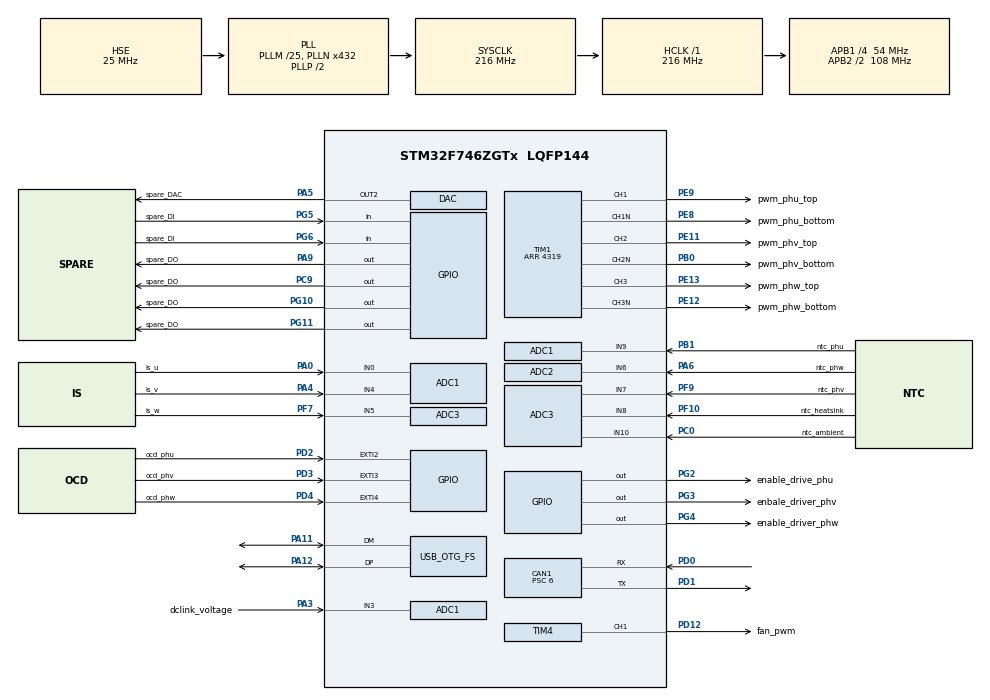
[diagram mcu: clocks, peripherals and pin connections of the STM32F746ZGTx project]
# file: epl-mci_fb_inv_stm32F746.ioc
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ADC1.Channel-0\#ChannelRegularConversion=ADC_CHANNEL_0
ADC1.Channel-1\#ChannelRegularConversion=ADC_CHANNEL_3
ADC1.Channel-2\#ChannelRegularConversion=ADC_CHANNEL_4
ADC1.Channel-3\#ChannelRegularConversion=ADC_CHANNEL_9
ADC1.ClockPrescaler=ADC_CLOCK_SYNC_PCLK_DIV4
ADC1.ContinuousConvMode=DISABLE
ADC1.DMAContinuousRequests=ENABLE
ADC1.EOCSelection=ADC_EOC_SEQ_CONV
ADC1.ExternalTrigConv=ADC_EXTERNALTRIGCONV_T1_TRGO2
ADC1.ExternalTrigConvEdge=ADC_EXTERNALTRIGCONVEDGE_RISING
ADC1.NbrOfConversion=4
ADC1.NbrOfConversionFlag=1
ADC1.Rank-0\#ChannelRegularConversion=1
ADC1.Rank-1\#ChannelRegularConversion=2
ADC1.Rank-2\#ChannelRegularConversion=3
ADC1.Rank-3\#ChannelRegularConversion=4
ADC1.SamplingTime-0\#ChannelRegularConversion=ADC_SAMPLETIME_3CYCLES
ADC1.SamplingTime-1\#ChannelRegularConversion=ADC_SAMPLETIME_3CYCLES
ADC1.SamplingTime-2\#ChannelRegularConversion=ADC_SAMPLETIME_3CYCLES
ADC1.SamplingTime-3\#ChannelRegularConversion=ADC_SAMPLETIME_3CYCLES
ADC1.master=1
ADC2.Channel-0\#ChannelRegularConversion=ADC_CHANNEL_0
ADC2.Channel-1\#ChannelRegularConversion=ADC_CHANNEL_3
ADC2.Channel-2\#ChannelRegularConversion=ADC_CHANNEL_4
ADC2.Channel-3\#ChannelRegularConversion=ADC_CHANNEL_6
ADC2.ClockPrescaler=ADC_CLOCK_SYNC_PCLK_DIV4
ADC2.ContinuousConvMode=DISABLE
ADC2.DMAContinuousRequests=ENABLE
ADC2.EOCSelection=ADC_EOC_SEQ_CONV
ADC2.ExternalTrigConv=ADC_EXTERNALTRIGCONV_T1_TRGO2
ADC2.ExternalTrigConvEdge=ADC_EXTERNALTRIGCONVEDGE_RISING
ADC2.NbrOfConversion=4
ADC2.NbrOfConversionFlag=1
ADC2.Rank-0\#ChannelRegularConversion=1
ADC2.Rank-1\#ChannelRegularConversion=2
ADC2.Rank-2\#ChannelRegularConversion=3
ADC2.Rank-3\#ChannelRegularConversion=4
ADC2.SamplingTime-0\#ChannelRegularConversion=ADC_SAMPLETIME_3CYCLES
ADC2.SamplingTime-1\#ChannelRegularConversion=ADC_SAMPLETIME_3CYCLES
ADC2.SamplingTime-2\#ChannelRegularConversion=ADC_SAMPLETIME_3CYCLES
ADC2.SamplingTime-3\#ChannelRegularConversion=ADC_SAMPLETIME_3CYCLES
ADC2.ScanConvMode=ADC_SCAN_ENABLE
ADC3.Channel-0\#ChannelRegularConversion=ADC_CHANNEL_0
ADC3.Channel-1\#ChannelRegularConversion=ADC_CHANNEL_3
ADC3.Channel-2\#ChannelRegularConversion=ADC_CHANNEL_5
ADC3.Channel-3\#ChannelRegularConversion=ADC_CHANNEL_7
ADC3.Channel-4\#ChannelRegularConversion=ADC_CHANNEL_8
ADC3.Channel-5\#ChannelRegularConversion=ADC_CHANNEL_10
ADC3.ClockPrescaler=ADC_CLOCK_SYNC_PCLK_DIV4
ADC3.ContinuousConvMode=DISABLE
ADC3.DMAContinuousRequests=ENABLE
ADC3.EOCSelection=ADC_EOC_SEQ_CONV
ADC3.ExternalTrigConv=ADC_EXTERNALTRIGCONV_T1_TRGO2
ADC3.ExternalTrigConvEdge=ADC_EXTERNALTRIGCONVEDGE_RISING
ADC3.NbrOfConversion=6
ADC3.NbrOfConversionFlag=1
ADC3.Rank-0\#ChannelRegularConversion=1
ADC3.Rank-1\#ChannelRegularConversion=2
ADC3.Rank-2\#ChannelRegularConversion=3
ADC3.Rank-3\#ChannelRegularConversion=4
ADC3.Rank-4\#ChannelRegularConversion=5
ADC3.Rank-5\#ChannelRegularConversion=6
ADC3.SamplingTime-0\#ChannelRegularConversion=ADC_SAMPLETIME_3CYCLES
ADC3.SamplingTime-1\#ChannelRegularConversion=ADC_SAMPLETIME_3CYCLES
ADC3.SamplingTime-2\#ChannelRegularConversion=ADC_SAMPLETIME_3CYCLES
ADC3.SamplingTime-3\#ChannelRegularConversion=ADC_SAMPLETIME_3CYCLES
ADC3.SamplingTime-4\#ChannelRegularConversion=ADC_SAMPLETIME_3CYCLES
ADC3.SamplingTime-5\#ChannelRegularConversion=ADC_SAMPLETIME_3CYCLES
CAN1.BS1=CAN_BS1_15TQ
CAN1.BS2=CAN_BS2_2TQ
CAN1.CalculateBaudRate=500000
CAN1.CalculateTimeBit=2000
CAN1.CalculateTimeQuantum=111.11111111111111
CAN1.Prescaler=6
CORTEX_M7.ART_ACCELERATOR_ENABLE=1
CORTEX_M7.CPU_DCache=Enabled
CORTEX_M7.CPU_ICache=Enabled
CORTEX_M7.FlashInterface=TCM_Enabled
CORTEX_M7.PREFETCH_ENABLE=1
Dma.ADC1.0.Direction=DMA_PERIPH_TO_MEMORY
Dma.ADC1.0.FIFOMode=DMA_FIFOMODE_DISABLE
Dma.ADC1.0.Instance=DMA2_Stream0
Dma.ADC1.0.MemDataAlignment=DMA_MDATAALIGN_HALFWORD
Dma.ADC1.0.MemInc=DMA_MINC_ENABLE
Dma.ADC1.0.Mode=DMA_CIRCULAR
Dma.ADC1.0.PeriphDataAlignment=DMA_PDATAALIGN_HALFWORD
Dma.ADC1.0.PeriphInc=DMA_PINC_DISABLE
Dma.ADC1.0.Priority=DMA_PRIORITY_VERY_HIGH
Dma.ADC2.1.Direction=DMA_PERIPH_TO_MEMORY
Dma.ADC2.1.FIFOMode=DMA_FIFOMODE_DISABLE
Dma.ADC2.1.Instance=DMA2_Stream2
Dma.ADC2.1.MemDataAlignment=DMA_MDATAALIGN_HALFWORD
Dma.ADC2.1.MemInc=DMA_MINC_ENABLE
Dma.ADC2.1.Mode=DMA_CIRCULAR
Dma.ADC2.1.PeriphDataAlignment=DMA_PDATAALIGN_HALFWORD
Dma.ADC2.1.PeriphInc=DMA_PINC_DISABLE
Dma.ADC2.1.Priority=DMA_PRIORITY_VERY_HIGH
Dma.ADC3.2.Direction=DMA_PERIPH_TO_MEMORY
Dma.ADC3.2.FIFOMode=DMA_FIFOMODE_DISABLE
Dma.ADC3.2.Instance=DMA2_Stream1
Dma.ADC3.2.MemDataAlignment=DMA_MDATAALIGN_HALFWORD
Dma.ADC3.2.MemInc=DMA_MINC_ENABLE
Dma.ADC3.2.Mode=DMA_CIRCULAR
Dma.ADC3.2.PeriphDataAlignment=DMA_PDATAALIGN_HALFWORD
Dma.ADC3.2.PeriphInc=DMA_PINC_DISABLE
Dma.ADC3.2.Priority=DMA_PRIORITY_VERY_HIGH
Dma.Request0=ADC1
Dma.Request1=ADC2
Dma.Request2=ADC3
Dma.Request3=TIM1_CH1/CH2/CH3
Dma.TIM1_CH1/CH2/CH3.3.Direction=DMA_MEMORY_TO_PERIPH
Dma.TIM1_CH1/CH2/CH3.3.FIFOMode=DMA_FIFOMODE_DISABLE
Dma.TIM1_CH1/CH2/CH3.3.Instance=DMA2_Stream6
Dma.TIM1_CH1/CH2/CH3.3.MemDataAlignment=DMA_MDATAALIGN_HALFWORD
Dma.TIM1_CH1/CH2/CH3.3.MemInc=DMA_MINC_ENABLE
Dma.TIM1_CH1/CH2/CH3.3.Mode=DMA_NORMAL
Dma.TIM1_CH1/CH2/CH3.3.PeriphDataAlignment=DMA_PDATAALIGN_HALFWORD
Dma.TIM1_CH1/CH2/CH3.3.PeriphInc=DMA_PINC_DISABLE
Dma.TIM1_CH1/CH2/CH3.3.Priority=DMA_PRIORITY_VERY_HIGH
IWDG.Reload=4
IWDG.Window=256
Mcu.Family=STM32F7
Mcu.Name=STM32F746ZGTx
Mcu.Package=LQFP144
NVIC.ADC_IRQn=true\:0\:0\:false\:false\:true\:true\:true\:true
NVIC.CAN1_RX0_IRQn=true\:0\:0\:false\:false\:true\:true\:true\:true
NVIC.DMA2_Stream0_IRQn=true\:0\:0\:false\:false\:true\:true\:true\:true
NVIC.DMA2_Stream1_IRQn=true\:0\:0\:false\:false\:true\:true\:true\:true
NVIC.DMA2_Stream2_IRQn=true\:0\:0\:false\:false\:true\:true\:true\:true
NVIC.DMA2_Stream6_IRQn=true\:0\:0\:false\:false\:true\:true\:true\:true
NVIC.EXTI2_IRQn=true\:0\:0\:false\:false\:true\:true\:true\:true
NVIC.EXTI3_IRQn=true\:0\:0\:false\:false\:true\:true\:true\:true
NVIC.EXTI4_IRQn=true\:0\:0\:false\:false\:true\:true\:true\:true
NVIC.PriorityGroup=NVIC_PRIORITYGROUP_4
NVIC.TIM2_IRQn=true\:0\:0\:false\:false\:true\:true\:true\:true
PA0/WKUP.GPIO_Label=is_u
PA0/WKUP.Signal=ADCx_IN0
PA11.Mode=Device_Only
PA11.Signal=USB_OTG_FS_DM
PA12.Mode=Device_Only
PA12.Signal=USB_OTG_FS_DP
PA13.Mode=JTAG_5_pins
PA13.Signal=SYS_JTMS-SWDIO
PA14.Mode=JTAG_5_pins
PA14.Signal=SYS_JTCK-SWCLK
PA15.Mode=JTAG_5_pins
PA15.Signal=SYS_JTDI
PA3.GPIO_Label=dclink_voltage
PA3.Signal=ADCx_IN3
PA4.GPIO_Label=is_v
PA4.Signal=ADCx_IN4
PA5.GPIO_Label=spare_DAC
PA5.Signal=COMP_DAC2_group
PA6.GPIO_Label=ntc_phw
PA6.Signal=ADCx_IN6
PA9.GPIO_Label=spare_DO
PA9.GPIO_PuPd=GPIO_PULLDOWN
PA9.GPIO_Speed=GPIO_SPEED_FREQ_LOW
PA9.Signal=GPIO_Output
PB0.GPIO_Label=pwm_phv_bottom
PB0.GPIO_ModeDefaultPP=GPIO_MODE_AF_PP
PB0.GPIO_PuPd=GPIO_PULLDOWN
PB0.GPIO_Speed=GPIO_SPEED_FREQ_VERY_HIGH
PB0.Mode=PWM Generation2 CH2 CH2N
PB0.Signal=TIM1_CH2N
PB1.GPIO_Label=ntc_phu
PB1.GPIO_PuPd=GPIO_NOPULL
PB1.Signal=ADCx_IN9
PB3.Mode=JTAG_5_pins
PB3.Signal=SYS_JTDO-SWO
PB4.Mode=JTAG_5_pins
PB4.Signal=SYS_JTRST
PC0.GPIO_Label=ntc_ambient
PC0.Signal=ADCx_IN10
PC14/OSC32_IN.Mode=LSE-External-Oscillator
PC14/OSC32_IN.Signal=RCC_OSC32_IN
PC15/OSC32_OUT.Mode=LSE-External-Oscillator
PC15/OSC32_OUT.Signal=RCC_OSC32_OUT
PC9.GPIO_Label=spare_DO
PC9.GPIO_PuPd=GPIO_PULLDOWN
PC9.GPIO_Speed=GPIO_SPEED_FREQ_VERY_HIGH
PC9.Signal=GPIO_Output
PD0.Mode=CAN_Activate
PD0.Signal=CAN1_RX
PD1.Mode=CAN_Activate
PD1.Signal=CAN1_TX
PD12.GPIO_Label=fan_pwm
PD12.GPIO_ModeDefaultPP=GPIO_MODE_AF_PP
PD12.GPIO_PuPd=GPIO_PULLDOWN
PD12.GPIO_Speed=GPIO_SPEED_FREQ_VERY_HIGH
PD12.Signal=S_TIM4_CH1
PD2.GPIO_Label=ocd_phu
PD2.GPIO_ModeDefaultEXTI=GPIO_MODE_IT_FALLING
PD2.GPIO_PuPd=GPIO_PULLDOWN
PD2.Signal=GPXTI2
PD3.GPIO_Label=ocd_phv
PD3.GPIO_ModeDefaultEXTI=GPIO_MODE_IT_FALLING
PD3.GPIO_PuPd=GPIO_PULLDOWN
PD3.Signal=GPXTI3
PD4.GPIO_Label=ocd_phw
PD4.GPIO_ModeDefaultEXTI=GPIO_MODE_IT_FALLING
PD4.GPIO_PuPd=GPIO_PULLDOWN
PD4.Signal=GPXTI4
PE11.GPIO_Label=pwm_phv_top
PE11.GPIO_ModeDefaultPP=GPIO_MODE_AF_PP
PE11.GPIO_PuPd=GPIO_PULLDOWN
PE11.GPIO_Speed=GPIO_SPEED_FREQ_VERY_HIGH
PE11.Signal=S_TIM1_CH2
PE12.GPIO_Label=pwm_phw_bottom
PE12.GPIO_ModeDefaultPP=GPIO_MODE_AF_PP
PE12.GPIO_PuPd=GPIO_PULLDOWN
PE12.GPIO_Speed=GPIO_SPEED_FREQ_VERY_HIGH
PE12.Mode=PWM Generation3 CH3 CH3N
PE12.Signal=TIM1_CH3N
PE13.GPIO_Label=pwm_phw_top
PE13.GPIO_ModeDefaultPP=GPIO_MODE_AF_PP
PE13.GPIO_PuPd=GPIO_PULLDOWN
PE13.GPIO_Speed=GPIO_SPEED_FREQ_VERY_HIGH
PE13.Signal=S_TIM1_CH3
PE8.GPIO_Label=pwm_phu_bottom
PE8.GPIO_ModeDefaultPP=GPIO_MODE_AF_PP
PE8.GPIO_PuPd=GPIO_PULLDOWN
PE8.GPIO_Speed=GPIO_SPEED_FREQ_VERY_HIGH
PE8.Mode=PWM Generation1 CH1 CH1N
PE8.Signal=TIM1_CH1N
PE9.GPIO_Label=pwm_phu_top
PE9.GPIO_ModeDefaultPP=GPIO_MODE_AF_PP
PE9.GPIO_PuPd=GPIO_PULLDOWN
PE9.GPIO_Speed=GPIO_SPEED_FREQ_VERY_HIGH
PE9.Signal=S_TIM1_CH1
PF10.GPIO_Label=ntc_heatsink
PF10.Mode=IN8
PF10.Signal=ADC3_IN8
PF7.GPIO_Label=is_w
PF7.Mode=IN5
PF7.Signal=ADC3_IN5
PF9.GPIO_Label=ntc_phv
PF9.Mode=IN7
PF9.Signal=ADC3_IN7
PG10.GPIO_Label=spare_DO
PG10.GPIO_PuPd=GPIO_PULLDOWN
PG10.GPIO_Speed=GPIO_SPEED_FREQ_VERY_HIGH
PG10.Signal=GPIO_Output
PG11.GPIO_Label=spare_DO
PG11.GPIO_PuPd=GPIO_PULLDOWN
PG11.GPIO_Speed=GPIO_SPEED_FREQ_VERY_HIGH
PG11.Signal=GPIO_Output
PG2.GPIO_Label=enable_drive_phu
PG2.GPIO_PuPd=GPIO_PULLDOWN
PG2.GPIO_Speed=GPIO_SPEED_FREQ_LOW
PG2.Signal=GPIO_Output
PG3.GPIO_Label=enbale_driver_phv
PG3.GPIO_PuPd=GPIO_PULLDOWN
PG3.GPIO_Speed=GPIO_SPEED_FREQ_LOW
PG3.Signal=GPIO_Output
PG4.GPIO_Label=enable_driver_phw
PG4.GPIO_PuPd=GPIO_PULLDOWN
PG4.GPIO_Speed=GPIO_SPEED_FREQ_LOW
PG4.Signal=GPIO_Output
PG5.GPIO_Label=spare_DI
PG5.GPIO_PuPd=GPIO_PULLDOWN
PG5.Signal=GPIO_Input
PG6.GPIO_Label=spare_DI
PG6.GPIO_PuPd=GPIO_PULLDOWN
PG6.Signal=GPIO_Input
PH0/OSC_IN.Mode=HSE-External-Oscillator
PH0/OSC_IN.Signal=RCC_OSC_IN
PH1/OSC_OUT.Mode=HSE-External-Oscillator
PH1/OSC_OUT.Signal=RCC_OSC_OUT
ProjectManager.HeapSize=0x200
ProjectManager.StackSize=0x400
ProjectManager.TargetToolchain=STM32CubeIDE
RCC.AHBFreq_Value=216000000
RCC.APB1CLKDivider=RCC_HCLK_DIV4
RCC.APB1Freq_Value=54000000
RCC.APB1TimFreq_Value=108000000
RCC.APB2CLKDivider=RCC_HCLK_DIV2
RCC.APB2Freq_Value=108000000
RCC.APB2TimFreq_Value=216000000
RCC.CortexFreq_Value=216000000
RCC.HCLKFreq_Value=216000000
RCC.HSE_VALUE=25000000
RCC.HSI_VALUE=16000000
RCC.PLLM=25
RCC.PLLN=432
RCC.PLLQ=9
RCC.SYSCLKFreq_VALUE=216000000
RCC.SYSCLKSource=RCC_SYSCLKSOURCE_PLLCLK
RCC.USBFreq_Value=48000000
RCC.VCOOutputFreq_Value=432000000
SH.ADCx_IN0.0=ADC1_IN0,IN0
SH.ADCx_IN0.1=ADC2_IN0,IN0
SH.ADCx_IN0.2=ADC3_IN0,IN0
SH.ADCx_IN10.0=ADC3_IN10,IN10
SH.ADCx_IN3.0=ADC1_IN3,IN3
SH.ADCx_IN3.1=ADC2_IN3,IN3
SH.ADCx_IN3.2=ADC3_IN3,IN3
SH.ADCx_IN4.0=ADC1_IN4,IN4
SH.ADCx_IN4.1=ADC2_IN4,IN4
SH.ADCx_IN6.0=ADC2_IN6,IN6
SH.ADCx_IN9.0=ADC1_IN9,IN9
SH.COMP_DAC2_group.0=DAC_OUT2,DAC_OUT2
SH.S_TIM1_CH1.0=TIM1_CH1,PWM Generation1 CH1 CH1N
SH.S_TIM1_CH2.0=TIM1_CH2,PWM Generation2 CH2 CH2N
SH.S_TIM1_CH3.0=TIM1_CH3,PWM Generation3 CH3 CH3N
SH.S_TIM4_CH1.0=TIM4_CH1,PWM Generation1 CH1
TIM1.Channel-PWM\ Generation1\ CH1\ CH1N=TIM_CHANNEL_1
TIM1.Channel-PWM\ Generation2\ CH2\ CH2N=TIM_CHANNEL_2
TIM1.Channel-PWM\ Generation3\ CH3\ CH3N=TIM_CHANNEL_3
TIM1.Channel-PWM\ Generation5\ No\ Output=TIM_CHANNEL_5
TIM1.CounterMode=TIM_COUNTERMODE_CENTERALIGNED2
TIM1.DeadTime=170
TIM1.OCMode_PWM-PWM\ Generation1\ CH1\ CH1N=TIM_OCMODE_PWM1
TIM1.OCMode_PWM-PWM\ Generation2\ CH2\ CH2N=TIM_OCMODE_PWM1
TIM1.OCMode_PWM-PWM\ Generation3\ CH3\ CH3N=TIM_OCMODE_PWM1
TIM1.OCMode_PWM-PWM\ Generation5\ No\ Output=TIM_OCMODE_PWM2
TIM1.Period=4319
TIM1.TIM_MasterOutputTrigger=TIM_TRGO_UPDATE
TIM1.TIM_MasterOutputTrigger2=TIM_TRGO2_UPDATE
TIM1.TIM_MasterSlaveMode=TIM_MASTERSLAVEMODE_ENABLE
TIM2.Channel-PWM\ Generation2\ No\ Output=TIM_CHANNEL_2
TIM2.Period=4318
TIM2.Pulse-PWM\ Generation2\ No\ Output=256
TIM2.TIM_MasterOutputTrigger=TIM_TRGO_ENABLE
TIM2.TIM_MasterSlaveMode=TIM_MASTERSLAVEMODE_ENABLE
TIM4.Channel-PWM\ Generation1\ CH1=TIM_CHANNEL_1
TIM4.CounterMode=TIM_COUNTERMODE_CENTERALIGNED1
TIM4.Period=5399
USB_OTG_FS.VirtualMode=Device_Only
VP_IWDG_VS_IWDG.Mode=IWDG_Activate
VP_TIM1_VS_ClockSourceINT.Mode=Internal
VP_TIM1_VS_ClockSourceITR.Mode=TriggerSource_ITR1
VP_TIM1_VS_ControllerModeGated.Mode=Gated Mode
VP_TIM1_VS_no_output5.Mode=PWM Generation5 No Output
VP_TIM2_VS_ClockSourceINT.Mode=Internal
VP_TIM2_VS_no_output2.Mode=PWM Generation2 No Output
VP_TIM4_VS_ClockSourceINT.Mode=Internal
board=custom

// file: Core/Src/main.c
/* USER CODE BEGIN Header */
/**
  ******************************************************************************
  * @file           : main.c
  * @brief          : Main program body
  ******************************************************************************
  * @attention
  *
  * Copyright (c) 2023 STMicroelectronics.
  * All rights reserved.
  *
  * This software is licensed under terms that can be found in the LICENSE file
  * in the root directory of this software component.
  * If no LICENSE file comes with this software, it is provided AS-IS.
  *
  ******************************************************************************
  */
/* USER CODE END Header */
#include "main.h"
#include "adc.h"
#include "can.h"
#include "dac.h"
#include "dma.h"
#include "iwdg.h"
#include "tim.h"
#include "usb_otg.h"
#include "gpio.h"

/* USER CODE BEGIN Includes */
#include "fb_state_machine.h"
/* USER CODE END Includes */

void SystemClock_Config(void);

int main(void)
{

  /* Enable I-Cache---------------------------------------------------------*/
  SCB_EnableICache();

  /* Enable D-Cache---------------------------------------------------------*/
  SCB_EnableDCache();

  /* MCU Configuration--------------------------------------------------------*/

  /* Reset of all peripherals, Initializes the Flash interface and the Systick. */
  HAL_Init();

  /* USER CODE BEGIN Init */
  /* time delay for voltage stabilization */
  HAL_Delay(1000);
  /* USER CODE END Init */

  /* Configure the system clock */
  SystemClock_Config();

  /* Initialize all configured peripherals */
  MX_GPIO_Init();
  MX_DMA_Init();
  MX_USB_OTG_FS_PCD_Init();
  MX_ADC1_Init();
  MX_ADC2_Init();
  MX_ADC3_Init();
  MX_TIM1_Init();
  MX_CAN1_Init();
  MX_DAC_Init();
  MX_TIM4_Init();
  MX_TIM2_Init();
  MX_IWDG_Init();
  /* USER CODE BEGIN 2 */

  peripherals_init();
  global_state_machine_init();

  /* USER CODE END 2 */

  /* Infinite loop */
  while (1)
  {

  }
}

void SystemClock_Config(void)
{
  RCC_OscInitTypeDef RCC_OscInitStruct = {0};
  RCC_ClkInitTypeDef RCC_ClkInitStruct = {0};

  /** Configure LSE Drive Capability
  */
  HAL_PWR_EnableBkUpAccess();

  /** Configure the main internal regulator output voltage
  */
  __HAL_RCC_PWR_CLK_ENABLE();
  __HAL_PWR_VOLTAGESCALING_CONFIG(PWR_REGULATOR_VOLTAGE_SCALE1);

  /** Initializes the RCC Oscillators according to the specified parameters
  * in the RCC_OscInitTypeDef structure.
  */
  RCC_OscInitStruct.OscillatorType = RCC_OSCILLATORTYPE_LSI|RCC_OSCILLATORTYPE_HSE;
  RCC_OscInitStruct.HSEState = RCC_HSE_ON;
  RCC_OscInitStruct.LSIState = RCC_LSI_ON;
  RCC_OscInitStruct.PLL.PLLState = RCC_PLL_ON;
  RCC_OscInitStruct.PLL.PLLSource = RCC_PLLSOURCE_HSE;
  RCC_OscInitStruct.PLL.PLLM = 25;
  RCC_OscInitStruct.PLL.PLLN = 432;
  RCC_OscInitStruct.PLL.PLLP = RCC_PLLP_DIV2;
  RCC_OscInitStruct.PLL.PLLQ = 9;
  if (HAL_RCC_OscConfig(&RCC_OscInitStruct) != HAL_OK)
  {
    Error_Handler();
  }

  /** Activate the Over-Drive mode
  */
  if (HAL_PWREx_EnableOverDrive() != HAL_OK)
  {
    Error_Handler();
  }

  /** Initializes the CPU, AHB and APB buses clocks
  */
  RCC_ClkInitStruct.ClockType = RCC_CLOCKTYPE_HCLK|RCC_CLOCKTYPE_SYSCLK
                              |RCC_CLOCKTYPE_PCLK1|RCC_CLOCKTYPE_PCLK2;
  RCC_ClkInitStruct.SYSCLKSource = RCC_SYSCLKSOURCE_PLLCLK;
  RCC_ClkInitStruct.AHBCLKDivider = RCC_SYSCLK_DIV1;
  RCC_ClkInitStruct.APB1CLKDivider = RCC_HCLK_DIV4;
  RCC_ClkInitStruct.APB2CLKDivider = RCC_HCLK_DIV2;

  if (HAL_RCC_ClockConfig(&RCC_ClkInitStruct, FLASH_LATENCY_7) != HAL_OK)
  {
    Error_Handler();
  }
}

void Error_Handler(void)
{
  __disable_irq();
  while (1)
  {
  }
}
